# KM1M7CF15 register map
Vendor: Nuvoton Technology Corporation Japan; Series: KM1M7CF; File version: 1.0.3
CPU: CM7 r1p2, little endian, MPU, FPU, double-precision FPU, I-cache, D-cache, ITCM, DTCM, 4 interrupt priority bits
Registers are 32-bit, read-write, no defined reset value unless marked. A register's access mark holds for its fields unless they carry their own. Offsets are from the block's base; [hi:lo] are bit positions; {n}, {i} and the like mark numbered series; 'fields as' and 'values as' point back to an identical list.

## PLM — Product life-cycle manager
Base 0x4001C3C0
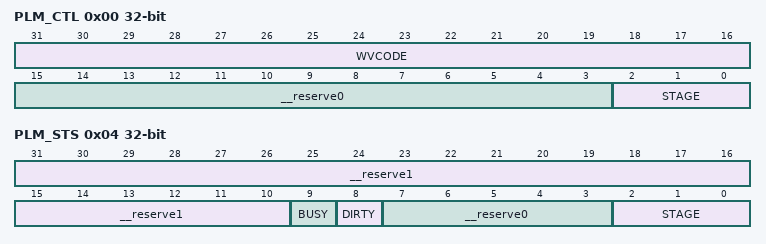
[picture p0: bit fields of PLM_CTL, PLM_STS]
0x00 PLM_CTL access per field — PLM Control Register
  [31:16] WVCODE rw — Write Verify Code
  [15:3] __reserve0 ro — "0" is always read out.
  [2:0] STAGE rw — Life-cycle Stage Update Bits
0x04 PLM_STS ro — PLM Status Register
  [31:10] __reserve1 — "0" is always read out.
  [9] BUSY — PLM Busy Bit
  [8] DIRTY — DIRTY Bit
  [7:3] __reserve0 — "0" is always read out.
  [2:0] STAGE — Life-cycle Current Stage

## FVC — Firmware version counter
Base 0x4001C3E4
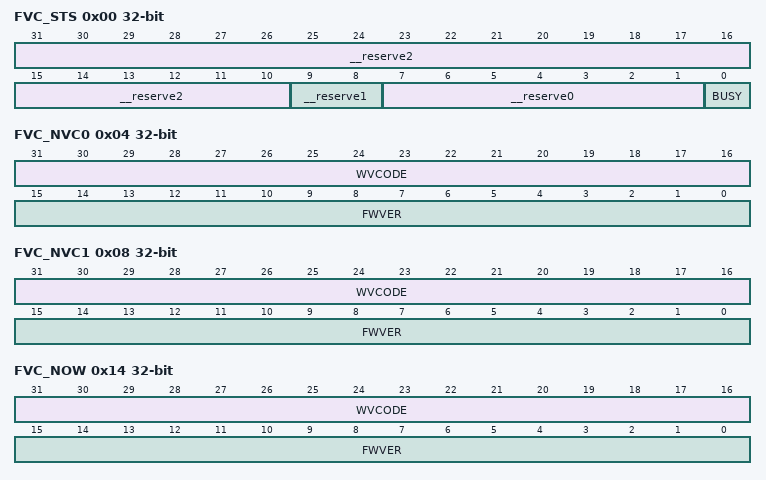
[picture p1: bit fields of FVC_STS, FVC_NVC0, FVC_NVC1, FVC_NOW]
0x00 FVC_STS ro — FVC Status Register
  [31:10] __reserve2 — "0" is always read out.
  [9:8] __reserve1 — Reserved.
  [7:1] __reserve0 — "0" is always read out.
  [0] BUSY — FVC Busy Bit
0x04 FVC_NVC0 — FVC Non-volatile Version Counter Control Register0
  [31:16] WVCODE — Verification Code
  [15:0] FWVER — Firmware Version
0x08 FVC_NVC1 — FVC Non-volatile Version Counter Control Register1
  [31:16] WVCODE — Verification Code
  [15:0] FWVER — Firmware Version
0x14 FVC_NOW — FVC current execution bank Counter Control Register0
  [31:16] WVCODE — Verification Code
  [15:0] FWVER — Firmware Version (NVC0 or NVC1)
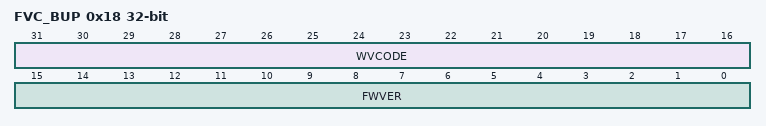
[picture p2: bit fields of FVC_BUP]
0x18 FVC_BUP — FVC current non-executed bank Counter Control Register0
  fields as FVC_NOW

## LIN
Base 0x40050274
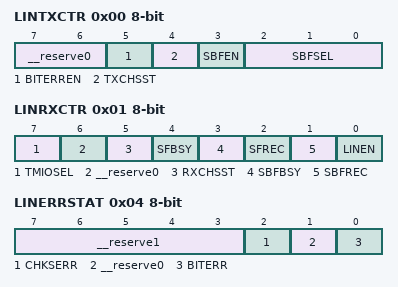
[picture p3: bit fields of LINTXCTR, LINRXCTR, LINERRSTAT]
0x00 LINTXCTR 8-bit access per field — LIN Transmission Control Register
  [7:6] __reserve0 ro — "0" is always read out.
  [5] BITERREN rw — Bit error detection function selection
  [4] TXCHSST rw — Checksum operation for transmission
  [3] SBFEN rw — Synch Break field transmission trigger/monitor (*1)
  [2:0] SBFSEL rw — Synch Break field transmission width selection
0x01 LINRXCTR 8-bit access per field — LIN Reception Control Register
  [7] TMIOSEL rw — Selection of clock source for Timer 12
  [6] __reserve0 rw — This bit must be set to "0".
  [5] RXCHSST rw — Checksum operation for reception
  [4] SFBSY ro — Synch field reception busy
  [3] SBFBSY ro — Synch Break field reception busy
  [2] SFREC rw — Enable Synch field reception
  [1] SBFREC rw — Enable Wake up signal and Synch Break field reception
  [0] LINEN rw — Enable LIN communication
0x04 LINERRSTAT 8-bit ro — LIN Error Status Register
  [7:3] __reserve1 — "0" is always read out.
  [2] CHKSERR — Checksum error detection (*1) (*2)
  [1] __reserve0 — "0" is always read out.
  [0] BITERR — Bit error detection (*3)
0x08 LINTXCHKS 8-bit ro — LIN Transmission Checksum Register
  [7:0] TXCHKS — Checksum value for the transmission data is read out.
0x09 LINRXCHKS 8-bit ro — LIN Reception Checksum Register
  [7:0] RXCHKS — Checksum value for the reception data is read out.

## CMP — Comparator
Base 0x40054000
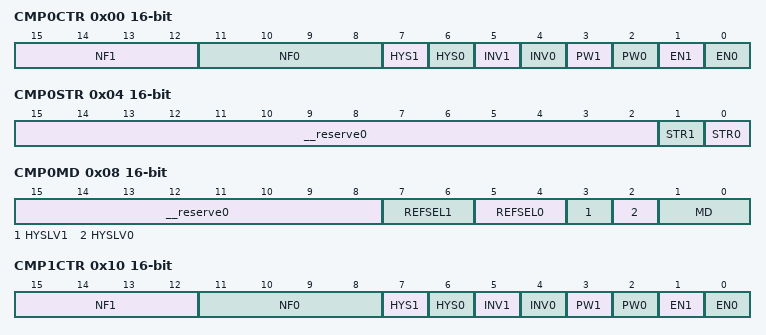
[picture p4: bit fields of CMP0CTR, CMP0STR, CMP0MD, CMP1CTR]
0x00 CMP0CTR 16-bit — Comparator 0 Control Register
  [15:12] NF1 — Selection of comparator n1 output noise filter
  [11:8] NF0 — Selection of comparator n0 output noise filter
  [7] HYS1 — CMPn1 hysteresis setting
  [6] HYS0 — CMPn0 hysteresis setting
  [5] INV1 — Selection of CMPn1 comparator detection polarity
  [4] INV0 — Selection of CMPn0 comparator detection polarity
  [3] PW1 — Operation of the CMPn1 comparator
  [2] PW0 — Operation of the CMPn0 comparator
  [1] EN1 — Start of the comparator n1 comparison
  [0] EN0 — Start of the comparator n0 comparison
0x04 CMP0STR 16-bit ro — Comparator 0 Status Register
  [15:2] __reserve0 — "0" is always read out.
  [1] STR1 — Detection state of CMPn1
  [0] STR0 — Detection state of CMPn0
0x08 CMP0MD 16-bit access per field — Comparator 0 Mode Register
  [15:8] __reserve0 ro — "0" is always read out.
  [7:6] REFSEL1 rw — CMPn1reference voltage
  [5:4] REFSEL0 rw — CMPn0 refernce voltage
  [3] HYSLV1 rw — CMPn1 hysteresis width (*)
  [2] HYSLV0 rw — CMPn0 hysteresis width (*)
  [1:0] MD rw — CMPn operating mode
0x10 CMP1CTR 16-bit — Comparator 1 Control Register
  fields as CMP0CTR
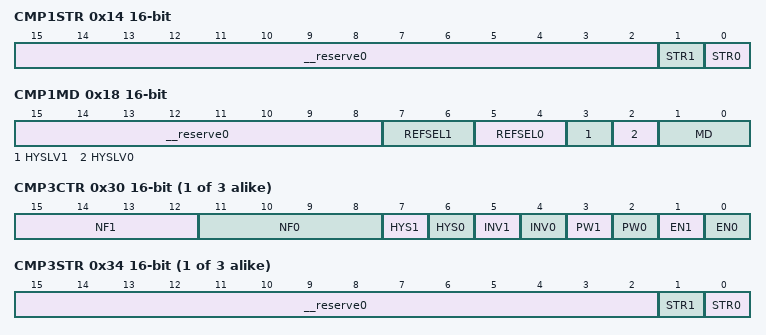
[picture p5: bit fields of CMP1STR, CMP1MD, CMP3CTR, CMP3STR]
0x14 CMP1STR 16-bit ro — Comparator 1 Status Register
  fields as CMP0STR
0x18 CMP1MD 16-bit access per field — Comparator 1 Mode Register
  fields as CMP0MD
{0x0+0x10*i} CMP{i}CTR 16-bit (i=3..5) — Comparator {i} Control Register
  fields as CMP0CTR
{0x4+0x10*i} CMP{i}STR 16-bit ro (i=3..5) — Comparator {i} Status Register
  fields as CMP0STR
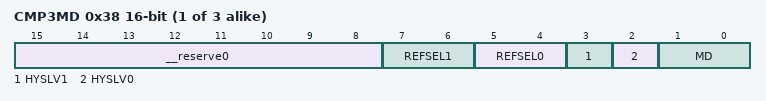
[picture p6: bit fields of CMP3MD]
{0x8+0x10*i} CMP{i}MD 16-bit access per field (i=3..5) — Comparator {i} Mode Register
  fields as CMP0MD

## PWRDET — Power Supply Voltage Detection
Base 0x40056000
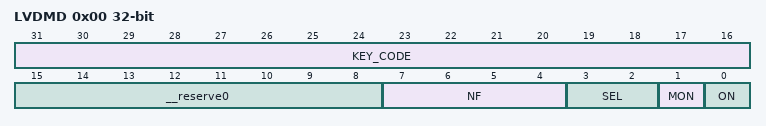
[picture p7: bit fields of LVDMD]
0x00 LVDMD access per field — Power Supply Voltage Detection Control Register
  [31:16] KEY_CODE wo — Register Key
  [15:8] __reserve0 ro — "0" is always read out.
  [7:4] NF rw — Selection of power supply voltage detection signal noise filter
  [3:2] SEL rw — Power supply voltage detection level selection (*)
  [1] MON ro — Power supply voltage monitor bit
  [0] ON rw — Power supply voltage detection function control

## TRNG
Base 0x40202000
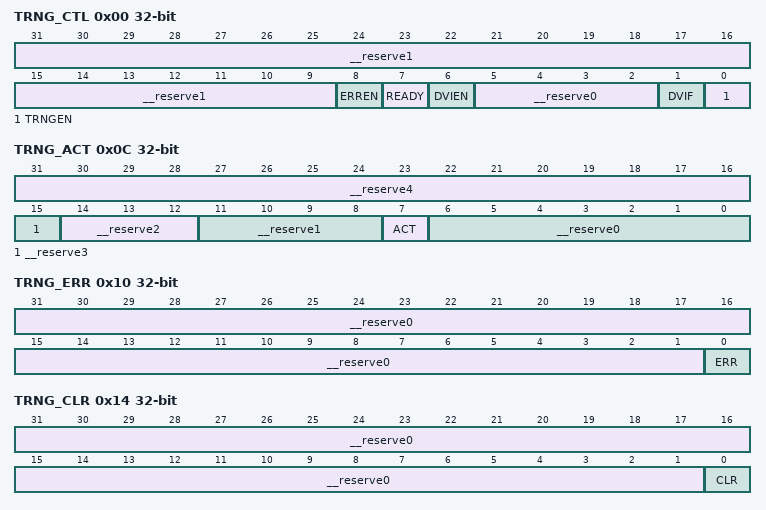
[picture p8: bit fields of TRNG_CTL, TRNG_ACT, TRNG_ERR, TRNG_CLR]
0x00 TRNG_CTL access per field — TRNG Control Register and Status
  [31:9] __reserve1 ro — "0" is always read out.
  [8] ERREN rw — TRNG Error detection Interrupt Enable Bit
  [7] READY ro — Random Number Generator Ready
  [6] DVIEN rw — Data Valid Interrupt Enable Bit
  [5:2] __reserve0 ro — "0" is always read out.
  [1] DVIF ro — Data Valid
  [0] TRNGEN rw — Random Number Generator Enable Bit
0x04 TRNG_DATA ro
  [31:0] DATA — Random Number
0x0C TRNG_ACT access per field — TRNG Activation Register
  [31:16] __reserve4 ro — "0" is always read out.
  [15] __reserve3 rw — Be sure to set this to "0".
  [14:12] __reserve2 ro — "0" is always read out.
  [11:8] __reserve1 rw — Be sure to set this to "0".
  [7] ACT rw — Random Number Generator Activation
  [6:0] __reserve0 ro — "0" is always read out.
0x10 TRNG_ERR ro — TRNG Error Detect Register
  [31:1] __reserve0 — "0" is always read out.
  [0] ERR — TRNG error flag
0x14 TRNG_CLR access per field — TRNG Error Clear Register
  [31:1] __reserve0 ro — "0" is always read out.
  [0] CLR rw — Clear TRNG error flag
